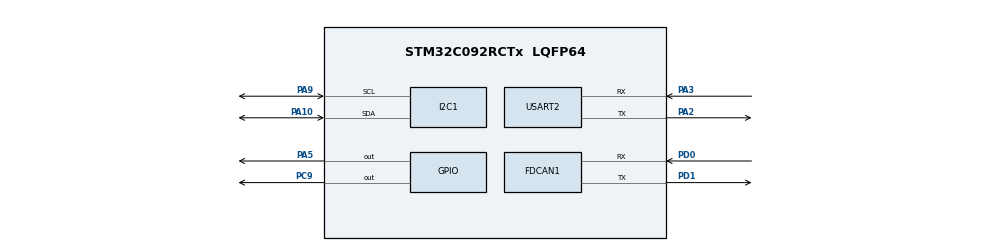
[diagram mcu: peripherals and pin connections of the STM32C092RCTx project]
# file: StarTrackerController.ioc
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Dma.Request0=USART2_TX
Dma.USART2_TX.0.Direction=DMA_MEMORY_TO_PERIPH
Dma.USART2_TX.0.EventEnable=DISABLE
Dma.USART2_TX.0.Instance=DMA1_Channel1
Dma.USART2_TX.0.MemDataAlignment=DMA_MDATAALIGN_BYTE
Dma.USART2_TX.0.MemInc=DMA_MINC_ENABLE
Dma.USART2_TX.0.Mode=DMA_NORMAL
Dma.USART2_TX.0.PeriphDataAlignment=DMA_PDATAALIGN_BYTE
Dma.USART2_TX.0.PeriphInc=DMA_PINC_DISABLE
Dma.USART2_TX.0.Polarity=HAL_DMAMUX_REQ_GEN_RISING
Dma.USART2_TX.0.Priority=DMA_PRIORITY_LOW
Dma.USART2_TX.0.RequestNumber=1
Dma.USART2_TX.0.SignalID=NONE
Dma.USART2_TX.0.SyncEnable=DISABLE
Dma.USART2_TX.0.SyncPolarity=HAL_DMAMUX_SYNC_NO_EVENT
Dma.USART2_TX.0.SyncRequestNumber=1
Dma.USART2_TX.0.SyncSignalID=NONE
FDCAN1.AutoRetransmission=ENABLE
FDCAN1.CalculateBaudRateNominal=500000
FDCAN1.CalculateTimeBitNominal=2000
FDCAN1.CalculateTimeQuantumNominal=41.666666666666664
FDCAN1.DataPrescaler=2
FDCAN1.DataSyncJumpWidth=12
FDCAN1.DataTimeSeg1=11
FDCAN1.DataTimeSeg2=12
FDCAN1.ExtFiltersNbr=0
FDCAN1.FrameFormat=FDCAN_FRAME_FD_BRS
FDCAN1.NominalPrescaler=2
FDCAN1.NominalSyncJumpWidth=12
FDCAN1.NominalTimeSeg1=35
FDCAN1.NominalTimeSeg2=12
FDCAN1.StdFiltersNbr=0
I2C1.Timing=0x10805D88
Mcu.Family=STM32C0
Mcu.Name=STM32C092RCTx
Mcu.Package=LQFP64
NVIC.DMA1_Channel1_IRQn=true\:0\:0\:false\:false\:true\:false\:true\:true
NVIC.USART2_IRQn=true\:0\:0\:false\:false\:true\:true\:true\:true
PA10.Mode=I2C
PA10.Signal=I2C1_SDA
PA13.GPIO_Label=SWDIO
PA13.Mode=Serial_Wire
PA13.Signal=DEBUG_SWDIO
PA14-BOOT0.GPIO_Label=SWCLK
PA14-BOOT0.Mode=Serial_Wire
PA14-BOOT0.Signal=DEBUG_SWCLK
PA2.GPIO_Speed=GPIO_SPEED_FREQ_VERY_HIGH
PA2.Mode=Asynchronous
PA2.Signal=USART2_TX
PA3.GPIO_Speed=GPIO_SPEED_FREQ_VERY_HIGH
PA3.Mode=Asynchronous
PA3.Signal=USART2_RX
PA5.Signal=GPIO_Output
PA9.Mode=I2C
PA9.Signal=I2C1_SCL
PC14-OSCX_IN(PC14).GPIO_Label=OSCX_IN
PC14-OSCX_IN(PC14).Signal=RCC_OSCX_IN
PC15-OSCX_OUT(PC15).GPIO_Label=OSCX_OUT
PC15-OSCX_OUT(PC15).Signal=RCC_OSCX_OUT
PC9.Signal=GPIO_Output
PD0.Mode=FDCAN_Activate
PD0.Signal=FDCAN1_RX
PD1.Mode=FDCAN_Activate
PD1.Signal=FDCAN1_TX
PF0-OSC_IN(PF0).GPIO_Label=OSC_IN
PF0-OSC_IN(PF0).Mode=HSE-External-Oscillator
PF0-OSC_IN(PF0).Signal=RCC_OSC_IN
PF1-OSC_OUT(PF1).GPIO_Label=OSC_OUT
PF1-OSC_OUT(PF1).Mode=HSE-External-Oscillator
PF1-OSC_OUT(PF1).Signal=RCC_OSC_OUT
ProjectManager.HeapSize=0x200
ProjectManager.StackSize=0x100
ProjectManager.TargetToolchain=Makefile
RCC.ADCFreq_Value=48000000
RCC.AHBFreq_Value=48000000
RCC.CortexFreq_Value=48000000
RCC.EXTERNAL_CLOCK_VALUE=12288000
RCC.HCLKFreq_Value=48000000
RCC.HSE_VALUE=48000000
RCC.HSI_VALUE=48000000
RCC.LSE_VALUE=32768
RCC.SYSCLKFreq_VALUE=48000000
RCC.SYSCLKSource=RCC_SYSCLKSOURCE_HSE
TIM2.Prescaler=47999
USART2.VirtualMode-Asynchronous=VM_ASYNC
VP_TIM2_VS_ClockSourceINT.Mode=Internal
board=NUCLEO-C092RC

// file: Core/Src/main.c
/* USER CODE BEGIN Header */
/**
  ******************************************************************************
  * @file           : main.c
  * @brief          : Main program body
  ******************************************************************************
  * @attention
  *
  * Copyright (c) 2025 STMicroelectronics.
  * All rights reserved.
  *
  * This software is licensed under terms that can be found in the LICENSE file
  * in the root directory of this software component.
  * If no LICENSE file comes with this software, it is provided AS-IS.
  *
  ******************************************************************************
  */
/* USER CODE END Header */
#include "main.h"

/* USER CODE BEGIN Includes */
#include "app.h"
/* USER CODE END Includes */

FDCAN_HandleTypeDef hfdcan1;

I2C_HandleTypeDef hi2c1;

TIM_HandleTypeDef htim2;

UART_HandleTypeDef huart2;
DMA_HandleTypeDef hdma_usart2_tx;

void SystemClock_Config(void);
static void MX_GPIO_Init(void);
static void MX_DMA_Init(void);
static void MX_USART2_UART_Init(void);
static void MX_FDCAN1_Init(void);
static void MX_I2C1_Init(void);
static void MX_TIM2_Init(void);

int main(void)
{

  /* MCU Configuration--------------------------------------------------------*/

  /* Reset of all peripherals, Initializes the Flash interface and the Systick. */
  HAL_Init();

  /* Configure the system clock */
  SystemClock_Config();

  /* Initialize all configured peripherals */
  MX_GPIO_Init();
  MX_DMA_Init();
  MX_USART2_UART_Init();
  MX_FDCAN1_Init();
  MX_I2C1_Init();
  MX_TIM2_Init();
  /* USER CODE BEGIN 2 */

  APP_Init();
  /* USER CODE END 2 */

  /* Infinite loop */
  /* USER CODE BEGIN WHILE */
  while (1)
  {
    APP_Handler();

    /* USER CODE END WHILE */

  }
}

void SystemClock_Config(void)
{
  RCC_OscInitTypeDef RCC_OscInitStruct = {0};
  RCC_ClkInitTypeDef RCC_ClkInitStruct = {0};

  __HAL_FLASH_SET_LATENCY(FLASH_LATENCY_1);

  /** Initializes the RCC Oscillators according to the specified parameters
  * in the RCC_OscInitTypeDef structure.
  */
  RCC_OscInitStruct.OscillatorType = RCC_OSCILLATORTYPE_HSE;
  RCC_OscInitStruct.HSEState = RCC_HSE_ON;
  if (HAL_RCC_OscConfig(&RCC_OscInitStruct) != HAL_OK)
  {
    Error_Handler();
  }

  /** Initializes the CPU, AHB and APB buses clocks
  */
  RCC_ClkInitStruct.ClockType = RCC_CLOCKTYPE_HCLK|RCC_CLOCKTYPE_SYSCLK
                              |RCC_CLOCKTYPE_PCLK1;
  RCC_ClkInitStruct.SYSCLKSource = RCC_SYSCLKSOURCE_HSE;
  RCC_ClkInitStruct.SYSCLKDivider = RCC_SYSCLK_DIV1;
  RCC_ClkInitStruct.AHBCLKDivider = RCC_HCLK_DIV1;
  RCC_ClkInitStruct.APB1CLKDivider = RCC_APB1_DIV1;

  if (HAL_RCC_ClockConfig(&RCC_ClkInitStruct, FLASH_LATENCY_1) != HAL_OK)
  {
    Error_Handler();
  }
}

static void MX_FDCAN1_Init(void)
{

  hfdcan1.Instance = FDCAN1;
  hfdcan1.Init.ClockDivider = FDCAN_CLOCK_DIV1;
  hfdcan1.Init.FrameFormat = FDCAN_FRAME_FD_BRS;
  hfdcan1.Init.Mode = FDCAN_MODE_NORMAL;
  hfdcan1.Init.AutoRetransmission = ENABLE;
  hfdcan1.Init.TransmitPause = DISABLE;
  hfdcan1.Init.ProtocolException = DISABLE;
  hfdcan1.Init.NominalPrescaler = 2;
  hfdcan1.Init.NominalSyncJumpWidth = 12;
  hfdcan1.Init.NominalTimeSeg1 = 35;
  hfdcan1.Init.NominalTimeSeg2 = 12;
  hfdcan1.Init.DataPrescaler = 2;
  hfdcan1.Init.DataSyncJumpWidth = 12;
  hfdcan1.Init.DataTimeSeg1 = 11;
  hfdcan1.Init.DataTimeSeg2 = 12;
  hfdcan1.Init.StdFiltersNbr = 0;
  hfdcan1.Init.ExtFiltersNbr = 0;
  hfdcan1.Init.TxFifoQueueMode = FDCAN_TX_FIFO_OPERATION;
  if (HAL_FDCAN_Init(&hfdcan1) != HAL_OK)
  {
    Error_Handler();
  }

}

static void MX_I2C1_Init(void)
{

  hi2c1.Instance = I2C1;
  hi2c1.Init.Timing = 0x10805D88;
  hi2c1.Init.OwnAddress1 = 0;
  hi2c1.Init.AddressingMode = I2C_ADDRESSINGMODE_7BIT;
  hi2c1.Init.DualAddressMode = I2C_DUALADDRESS_DISABLE;
  hi2c1.Init.OwnAddress2 = 0;
  hi2c1.Init.OwnAddress2Masks = I2C_OA2_NOMASK;
  hi2c1.Init.GeneralCallMode = I2C_GENERALCALL_DISABLE;
  hi2c1.Init.NoStretchMode = I2C_NOSTRETCH_DISABLE;
  if (HAL_I2C_Init(&hi2c1) != HAL_OK)
  {
    Error_Handler();
  }

  /** Configure Analogue filter
  */
  if (HAL_I2CEx_ConfigAnalogFilter(&hi2c1, I2C_ANALOGFILTER_ENABLE) != HAL_OK)
  {
    Error_Handler();
  }

  /** Configure Digital filter
  */
  if (HAL_I2CEx_ConfigDigitalFilter(&hi2c1, 0) != HAL_OK)
  {
    Error_Handler();
  }

}

static void MX_TIM2_Init(void)
{

  TIM_ClockConfigTypeDef sClockSourceConfig = {0};
  TIM_MasterConfigTypeDef sMasterConfig = {0};

  htim2.Instance = TIM2;
  htim2.Init.Prescaler = 47999;
  htim2.Init.CounterMode = TIM_COUNTERMODE_UP;
  htim2.Init.Period = 4294967295;
  htim2.Init.ClockDivision = TIM_CLOCKDIVISION_DIV1;
  htim2.Init.AutoReloadPreload = TIM_AUTORELOAD_PRELOAD_DISABLE;
  if (HAL_TIM_Base_Init(&htim2) != HAL_OK)
  {
    Error_Handler();
  }
  sClockSourceConfig.ClockSource = TIM_CLOCKSOURCE_INTERNAL;
  if (HAL_TIM_ConfigClockSource(&htim2, &sClockSourceConfig) != HAL_OK)
  {
    Error_Handler();
  }
  sMasterConfig.MasterOutputTrigger = TIM_TRGO_RESET;
  sMasterConfig.MasterSlaveMode = TIM_MASTERSLAVEMODE_DISABLE;
  if (HAL_TIMEx_MasterConfigSynchronization(&htim2, &sMasterConfig) != HAL_OK)
  {
    Error_Handler();
  }

}

static void MX_USART2_UART_Init(void)
{

  huart2.Instance = USART2;
  huart2.Init.BaudRate = 115200;
  huart2.Init.WordLength = UART_WORDLENGTH_8B;
  huart2.Init.StopBits = UART_STOPBITS_1;
  huart2.Init.Parity = UART_PARITY_NONE;
  huart2.Init.Mode = UART_MODE_TX_RX;
  huart2.Init.HwFlowCtl = UART_HWCONTROL_NONE;
  huart2.Init.OverSampling = UART_OVERSAMPLING_16;
  huart2.Init.OneBitSampling = UART_ONE_BIT_SAMPLE_DISABLE;
  huart2.Init.ClockPrescaler = UART_PRESCALER_DIV1;
  huart2.AdvancedInit.AdvFeatureInit = UART_ADVFEATURE_NO_INIT;
  if (HAL_UART_Init(&huart2) != HAL_OK)
  {
    Error_Handler();
  }

}

static void MX_DMA_Init(void)
{

  /* DMA controller clock enable */
  __HAL_RCC_DMA1_CLK_ENABLE();

  /* DMA interrupt init */
  /* DMA1_Channel1_IRQn interrupt configuration */
  HAL_NVIC_SetPriority(DMA1_Channel1_IRQn, 0, 0);
  HAL_NVIC_EnableIRQ(DMA1_Channel1_IRQn);

}

static void MX_GPIO_Init(void)
{
  GPIO_InitTypeDef GPIO_InitStruct = {0};

  /* GPIO Ports Clock Enable */
  __HAL_RCC_GPIOC_CLK_ENABLE();
  __HAL_RCC_GPIOF_CLK_ENABLE();
  __HAL_RCC_GPIOA_CLK_ENABLE();
  __HAL_RCC_GPIOD_CLK_ENABLE();

  /*Configure GPIO pin Output Level */
  HAL_GPIO_WritePin(GPIOA, GPIO_PIN_5, GPIO_PIN_RESET);

  /*Configure GPIO pin Output Level */
  HAL_GPIO_WritePin(GPIOC, GPIO_PIN_9, GPIO_PIN_RESET);

  /*Configure GPIO pin : PA5 */
  GPIO_InitStruct.Pin = GPIO_PIN_5;
  GPIO_InitStruct.Mode = GPIO_MODE_OUTPUT_PP;
  GPIO_InitStruct.Pull = GPIO_NOPULL;
  GPIO_InitStruct.Speed = GPIO_SPEED_FREQ_LOW;
  HAL_GPIO_Init(GPIOA, &GPIO_InitStruct);

  /*Configure GPIO pin : PC9 */
  GPIO_InitStruct.Pin = GPIO_PIN_9;
  GPIO_InitStruct.Mode = GPIO_MODE_OUTPUT_PP;
  GPIO_InitStruct.Pull = GPIO_NOPULL;
  GPIO_InitStruct.Speed = GPIO_SPEED_FREQ_LOW;
  HAL_GPIO_Init(GPIOC, &GPIO_InitStruct);

}

void Error_Handler(void)
{
  __disable_irq();
  while (1)
  {
  }
}
